AUTOSAR XML (schema 00046)
package /ComponentTypes
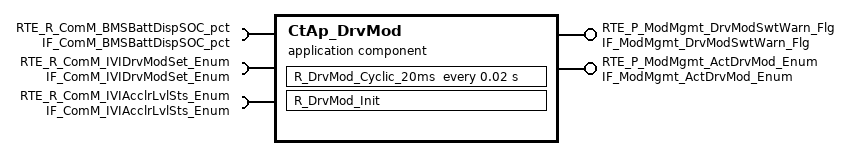
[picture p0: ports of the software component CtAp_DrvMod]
  application sw component type CtAp_DrvMod
    provide port RTE_P_ModMgmt_DrvModSwtWarn_Flg: nonqueued-sender-com-spec{data-element=tec_ModMgmt_DrvModSwtWarn_Flg, init-value=0}, provided-interface=IF_ModMgmt_DrvModSwtWarn_Flg
    require port RTE_R_ComM_BMSBattDispSOC_pct: nonqueued-receiver-com-spec{data-element=tec_ComM_BMSBattDispSOC_pct, filter=data-filter-type=ALWAYS, init-value=0}, required-interface=IF_ComM_BMSBattDispSOC_pct
    require port RTE_R_ComM_IVIDrvModSet_Enum: nonqueued-receiver-com-spec{data-element=tec_ComM_IVIDrvModSet_Enum, filter=data-filter-type=ALWAYS, init-value=0}, required-interface=IF_ComM_IVIDrvModSet_Enum
    require port RTE_R_ComM_IVIAcclrLvlSts_Enum: nonqueued-receiver-com-spec{data-element=tec_ComM_IVIAcclrLvlSts_Enum, filter=data-filter-type=ALWAYS, init-value=0}, required-interface=IF_ComM_IVIAcclrLvlSts_Enum
    provide port RTE_P_ModMgmt_ActDrvMod_Enum: nonqueued-sender-com-spec{data-element=tec_ModMgmt_ActDrvMod_Enum, init-value=0}, provided-interface=IF_ModMgmt_ActDrvMod_Enum
    behavior CtAp_DrvMod_InternalBehavior
      init event CtAp_DrvMod_InitEvent: start-on-event=R_DrvMod_Init
      timing event TMT_R_DrvMod_Cyclic_20ms: start-on-event=R_DrvMod_Cyclic_20ms, period=0.02
      runnable R_DrvMod_Init
      runnable R_DrvMod_Cyclic_20ms
        data-receive-point-by-arguments:
          access REC_RTE_R_ComM_BMSBattDispSOC_pct_tec_ComM_BMSBattDispSOC_pct: accessed-variable=RTE_R_ComM_BMSBattDispSOC_pct.tec_ComM_BMSBattDispSOC_pct
          access REC_RTE_R_ComM_IVIAcclrLvlSts_Enum_tec_ComM_IVIAcclrLvlSts_Enum: accessed-variable=RTE_R_ComM_IVIAcclrLvlSts_Enum.tec_ComM_IVIAcclrLvlSts_Enum
          access REC_RTE_R_ComM_IVIDrvModSet_Enum_tec_ComM_IVIDrvModSet_Enum: accessed-variable=RTE_R_ComM_IVIDrvModSet_Enum.tec_ComM_IVIDrvModSet_Enum
        data-send-points:
          access SEND_RTE_P_ModMgmt_ActDrvMod_Enum_tec_ModMgmt_ActDrvMod_Enum: accessed-variable=RTE_P_ModMgmt_ActDrvMod_Enum.tec_ModMgmt_ActDrvMod_Enum
          access SEND_RTE_P_ModMgmt_DrvModSwtWarn_Flg_tec_ModMgmt_DrvModSwtWarn_Flg: accessed-variable=RTE_P_ModMgmt_DrvModSwtWarn_Flg.tec_ModMgmt_DrvModSwtWarn_Flg
  swc implementation CtAp_DrvMod_Implementation: behavior=CtAp_DrvMod_InternalBehavior
    code-descriptors:
      code Default: artifact-descriptors=autosar-engineering-object=category=SWOBJ
